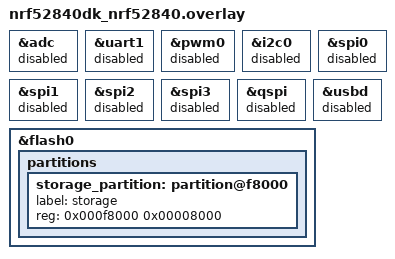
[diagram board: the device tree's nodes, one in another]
/* Copyright (c) 2020 Nordic Semiconductor ASA
 *
 * SPDX-License-Identifier: LicenseRef-Nordic-5-Clause
 */

&adc {
	status = "disabled";
};

&uart1 {
	status = "disabled";
};

&pwm0 {
	status = "disabled";
};

&i2c0 {
	status = "disabled";
};

&spi0 {
	status = "disabled";
};

&spi1 {
	status = "disabled";
};

&spi2 {
	status = "disabled";
};

&spi3 {
	status = "disabled";
};

&qspi {
	status = "disabled";
};

&usbd {
	status = "disabled";
};

&flash0 {
    partitions {
        storage_partition: partition@f8000 {
            label = "storage";
            reg = <0x000f8000 0x00008000>; // 示例：从 992KB 开始，大小 32KB
        };
    };
};
